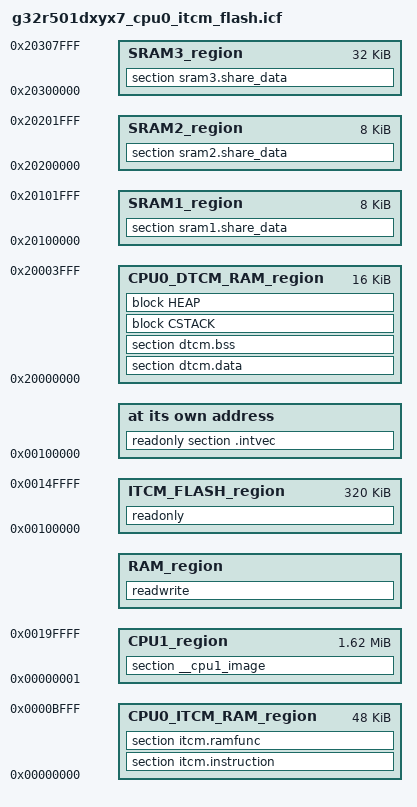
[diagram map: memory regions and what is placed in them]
/*###ICF### Section handled by ICF editor, don't touch! ****/
/*-Editor annotation file-*/
/* IcfEditorFile="$TOOLKIT_DIR$\config\linker\Geehy\IcfEditor\g32r501.xml" */
/*-Specials-*/
define symbol __ICFEDIT_intvec_start__ = 0x00100000;
/*-Memory Regions-*/
define symbol __ICFEDIT_region_CBUS_FLASH_start__    = 0x0;
define symbol __ICFEDIT_region_CBUS_FLASH_end__      = 0x0;
define symbol __ICFEDIT_region_ITCM_FLASH_start__    = 0x00100000;
define symbol __ICFEDIT_region_ITCM_FLASH_end__      = 0x0014FFFF;
define symbol __ICFEDIT_region_CPU0_ITCM_RAM_start__ = 0x00000000;
define symbol __ICFEDIT_region_CPU0_ITCM_RAM_end__   = 0x0000BFFF;
define symbol __ICFEDIT_region_CPU1_ITCM_RAM_start__ = 0x0;
define symbol __ICFEDIT_region_CPU1_ITCM_RAM_end__   = 0x0;
define symbol __ICFEDIT_region_CPU0_DTCM_RAM_start__ = 0x20000000;
define symbol __ICFEDIT_region_CPU0_DTCM_RAM_end__   = 0x20003FFF;
define symbol __ICFEDIT_region_CPU1_DTCM_RAM_start__ = 0x0;
define symbol __ICFEDIT_region_CPU1_DTCM_RAM_end__   = 0x0;
define symbol __ICFEDIT_region_SRAM1_start__         = 0x20100000;
define symbol __ICFEDIT_region_SRAM1_end__           = 0x20101FFF;
define symbol __ICFEDIT_region_SRAM2_start__         = 0x20200000;
define symbol __ICFEDIT_region_SRAM2_end__           = 0x20201FFF;
define symbol __ICFEDIT_region_SRAM3_start__         = 0x20300000;
define symbol __ICFEDIT_region_SRAM3_end__           = 0x20307FFF;

define exported symbol cpu1_image_start     =        __ICFEDIT_region_CBUS_FLASH_end__ + 1;
define exported symbol cpu1_image_end       =        0x0019FFFF;

/*-Sizes-*/
define symbol __ICFEDIT_size_cstack__     = 0x1000;
define symbol __ICFEDIT_size_heap__       = 0x1000;
/**** End of ICF editor section. ###ICF###*/

define memory mem with size = 4G;
define region CBUS_FLASH_region    = mem:[from __ICFEDIT_region_CBUS_FLASH_start__ to __ICFEDIT_region_CBUS_FLASH_end__];
define region ITCM_FLASH_region    = mem:[from __ICFEDIT_region_ITCM_FLASH_start__ to __ICFEDIT_region_ITCM_FLASH_end__];
define region CPU0_ITCM_RAM_region = mem:[from __ICFEDIT_region_CPU0_ITCM_RAM_start__ to __ICFEDIT_region_CPU0_ITCM_RAM_end__];
define region CPU1_ITCM_RAM_region = mem:[from __ICFEDIT_region_CPU1_ITCM_RAM_start__ to __ICFEDIT_region_CPU1_ITCM_RAM_end__];
define region CPU0_DTCM_RAM_region = mem:[from __ICFEDIT_region_CPU0_DTCM_RAM_start__ to __ICFEDIT_region_CPU0_DTCM_RAM_end__];
define region CPU1_DTCM_RAM_region = mem:[from __ICFEDIT_region_CPU1_DTCM_RAM_start__ to __ICFEDIT_region_CPU1_DTCM_RAM_end__];
define region SRAM1_region         = mem:[from __ICFEDIT_region_SRAM1_start__ to __ICFEDIT_region_SRAM1_end__];
define region SRAM2_region         = mem:[from __ICFEDIT_region_SRAM2_start__ to __ICFEDIT_region_SRAM2_end__];
define region SRAM3_region         = mem:[from __ICFEDIT_region_SRAM3_start__ to __ICFEDIT_region_SRAM3_end__];
define region CPU1_region          = mem:[from cpu1_image_start to cpu1_image_end];


define region RAM_region = CPU0_ITCM_RAM_region | CPU1_ITCM_RAM_region
                         | CPU0_DTCM_RAM_region | CPU1_DTCM_RAM_region
                         | SRAM1_region | SRAM2_region | SRAM3_region;

define block CSTACK     with alignment = 8, size = __ICFEDIT_size_cstack__     { };
define block HEAP       with alignment = 8, size = __ICFEDIT_size_heap__       { };

do not initialize  { section .noinit };

initialize by copy { readwrite,  section dtcm.data, section sram1.share_data,
    section sram2.share_data, section sram3.share_data };
initialize manually { section itcm.instruction, section itcm.ramfunc };

if (isdefinedsymbol(__USE_DLIB_PERTHREAD))
{
  // Required in a multi-threaded application
  initialize by copy with packing = none { section __DLIB_PERTHREAD };
}

place at address mem:__ICFEDIT_intvec_start__ { readonly section .intvec };

place in ITCM_FLASH_region  { readonly };
place in CPU0_ITCM_RAM_region  { section itcm.instruction, section itcm.ramfunc };
place in CPU0_DTCM_RAM_region  { section dtcm.data, section dtcm.bss, block CSTACK, block HEAP };
place in SRAM1_region  { section sram1.share_data };
place in SRAM2_region  { section sram2.share_data };
place in SRAM3_region  { section sram3.share_data };
place in RAM_region    { readwrite };
place in CPU1_region   { section __cpu1_image };
